# RZN2H register map
Vendor: Renesas Electronics Corporation; Series: RZN; File version: 1.00.00
CPU: other r0p0, little endian, MPU, no FPU, VTOR, 4 interrupt priority bits, 624 interrupts
Registers are 32-bit, read-write, reset 0x0 unless marked. A register's access mark holds for its fields unless they carry their own. Offsets are from the block's base; [hi:lo] are bit positions; {n}, {i} and the like mark numbered series; 'fields as' and 'values as' point back to an identical list; <NAME> marks a mode.

## DSMIF0 — Delta-sigma Interface 0
Base 0x90020000
Same registers: DSMIF1 0x90021000, DSMIF2 0x90022000, DSMIF3 0x90023000, DSMIF4 0x90024000, DSMIF5 0x90025000, DSMIF6 0x90120000, DSMIF7 0x90121000, DSMIF8 0x90122000, DSMIF9 0x90123000
0x00 DSCCSCR — Core Clock Selection Control Register
  [0] CLKSEL
    0=250 MHz; 1=400 MHz
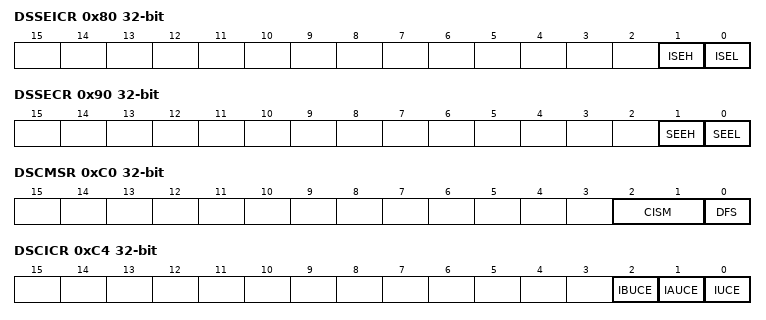
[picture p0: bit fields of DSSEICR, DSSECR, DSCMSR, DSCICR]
0x80 DSSEICR — Overcurrent Sum Error Detect Interrupt Control Register
  [1] ISEH — Overcurrent sum error upper limit detection interrupt enable bit
    0=Do not output overcurrent sum error upper limit detection interrupt; 1=Overcurrent sum error lower upper detection interrupt can be output
  [0] ISEL — Overcurrent sum error lower limit detection interrupt enable bit
    0=Do not output overcurrent sum error lower limit detection interrupt; 1=Overcurrent sum error lower limit detection interrupt can be output
0x84 DSSECSR — Overcurrent Sum Error Detect Channel Setting Register
  [2:0] SEDM — Overcurrent sum error detect mode setting bit
    0=Detects error of sum value of overcurrent data of CH0, CH1, CH2; 1=Detects error of sum value of overcurrent data of CH0, CH1; 2=Detects error of overcurrent data of CH0; 3=Detects error of overcurrent data of CH1; 4=Detects error of overcurrent data of CH2; other=Others (Setting prohibited (detects error of sum value of overcurrent data of CH0, CH1, CH2))
0x88 DSSELTR — Overcurrent Sum Error Detect Low Threshold Register
  [17:0] SCMPTBL — Overcurrent sum error detect lower limit
0x8C DSSEHTR — Overcurrent Sum Error Detect High Threshold Register
  [17:0] SCMPTBH — Overcurrent sum error detect upper limit
0x90 DSSECR — Overcurrent Sum Error Detect Control Register
  [1] SEEH — Overcurrent sum error upper limit detection enable bit
    0=The upper limit exceeded detection function of overcurrent sum error detection is invalid; 1=The upper limit exceeded detection function of overcurrent sum error detection is valid
  [0] SEEL — Overcurrent sum error lower limit detection enable bit
    0=The lower limit exceeded detection function of overcurrent sum error detection is invalid; 1=The lower limit exceeded detection function of overcurrent sum error detection is valid
{0xA0+4i} DSSECDR{i} (i=0..2) — Overcurrent Sum Error Detect Capture Data Register {i}
  [15:0] SECDR — Overcurrent sum error detect capture data n
0xC0 DSCMSR — Common Mode Setting Register
  [2:1] CISM — Common Interrupt Synchronous channel Mode
    0=Common interrupts are not used; 1=Common interrupts for ch0, ch1, and ch2 can be used; 2=Common interrupts for ch0 and ch1 can be used; 3=Setting prohibited
  [0] DFS — Data Format Select
    0=Left justified; 1=Right justified
0xC4 DSCICR — Common Interrupt Control Register
  [2] IBUCE — Capture current data register B update channel common interrupt enable
    0=Do not output capture current data register B update channel common interrupt; 1=Capture current data register B update channel common interrupt can be output
  [1] IAUCE — Capture current data register A update channel common interrupt enable
    0=Do not output capture current data register A update channel common interrupt; 1=Capture current data register A update channel common interrupt can be output
  [0] IUCE — Current data register update channel common interrupt enable
    0=Do not output capture current data register update channel common interrupt; 1=Capture current data register update channel common interrupt can be output
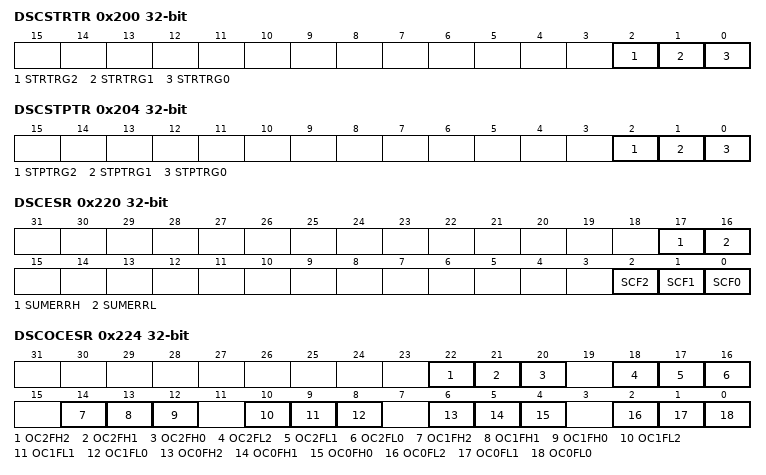
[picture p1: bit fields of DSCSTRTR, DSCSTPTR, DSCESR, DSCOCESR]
0x200 DSCSTRTR — Channel Software Start Trigger Register
  [all] fields
    0=Do nothing; 1=Start channel
  [2] STRTRG2 — Channel 2 start trigger
  [1] STRTRG1 — Channel 1 start trigger
  [0] STRTRG0 — Channel 0 start trigger
0x204 DSCSTPTR — Channel Software Stop Trigger Register
  [all] fields
    0=Do nothing; 1=Stop channel
  [2] STPTRG2 — Channel 2 stop trigger
  [1] STPTRG1 — Channel 1 stop trigger
  [0] STPTRG0 — Channel 0 stop trigger
0x220 DSCESR ro — Channel Error Status Register
  [17] SUMERRH — Overcurrent sum error upper limit detection flag
    0=Indicates that the sum value of overcurrent data is not more than the upper limit; 1=Indicates that the sum value of overcurrent data is more than the upper limit
  [16] SUMERRL — Overcurrent sum error lower limit detection flag
    0=Indicates that the sum value of overcurrent data is not less than the lower limit; 1=Indicates that the sum value of overcurrent data is less than the lower limit
  [2] SCF2 — Channel 2 short circuit detection flag
    0=Indicates that the MDATm2 pin short circuit is not detected; 1=Indicates that a short circuit on the MDATm2 pin has been detected
  [1] SCF1 — Channel 1 short circuit detection flag
    0=Indicates that the MDATm1 pin short circuit is not detected; 1=Indicates that a short circuit on the MDATm1 pin has been detected
  [0] SCF0 — Channel 0 short circuit detection flag
    0=Indicates that the MDATm0 pin short circuit is not detected; 1=Indicates that a short circuit on the MDATm0 pin has been detected
0x224 DSCOCESR ro — Channel Overcurrent Error Status Register
  [22] OC2FH2 — Channel 2 overcurrent upper limit exceeded 2 flag
    0=Indicates that the overcurrent data doesn't exceed the upper limit 2; 1=Indicates that the overcurrent data has exceeded the upper limit 2
  [21] OC2FH1 — Channel 1 overcurrent upper limit exceeded 2 flag
    values as OC2FH2
  [20] OC2FH0 — Channel 0 overcurrent upper limit exceeded 2 flag
    values as OC2FH2
  [18] OC2FL2 — Channel 2 overcurrent lower limit detection 2 flag
    0=Indicates that the overcurrent data is not less than the lower limit 2; 1=Indicates that the overcurrent data has been less than the lower limit 2
  [17] OC2FL1 — Channel 1 overcurrent lower limit detection 2 flag
    values as OC2FL2
  [16] OC2FL0 — Channel 0 overcurrent lower limit detection 2 flag
    values as OC2FL2
  [14] OC1FH2 — Channel 2 overcurrent upper limit exceeded 1 flag
    0=Indicates that the overcurrent data doesn't exceed the upper limit 1; 1=Indicates that the overcurrent data has exceeded the upper limit 1
  [13] OC1FH1 — Channel 1 overcurrent upper limit exceeded 1 flag
    values as OC1FH2
  [12] OC1FH0 — Channel 0 overcurrent upper limit exceeded 1 flag
    values as OC1FH2
  [10] OC1FL2 — Channel 2 overcurrent lower limit detection 1 flag
    0=Indicates that the overcurrent data is not less than the lower limit 1; 1=Indicates that the overcurrent data has been less than the lower limit 1
  [9] OC1FL1 — Channel 1 overcurrent lower limit detection 1 flag
    values as OC1FL2
  [8] OC1FL0 — Channel 0 overcurrent lower limit detection 1 flag
    values as OC1FL2
  [6] OC0FH2 — Channel 2 overcurrent upper limit exceeded 0 flag
    0=Indicates that the overcurrent data doesn't exceed the upper limit 0; 1=Indicates that the overcurrent data has exceeded the upper limit 0
  [5] OC0FH1 — Channel 1 overcurrent upper limit exceeded 0 flag
    values as OC0FH2
  [4] OC0FH0 — Channel 0 overcurrent upper limit exceeded 0 flag
    values as OC0FH2
  [2] OC0FL2 — Channel 2 overcurrent lower limit detection 0 flag
    0=Indicates that the overcurrent data is not less than the lower limit 0; 1=Indicates that the overcurrent data has been less than the lower limit 0
  [1] OC0FL1 — Channel 1 overcurrent lower limit detection 0 flag
    values as OC0FL2
  [0] OC0FL0 — Channel 0 overcurrent lower limit detection 0 flag
    values as OC0FL2
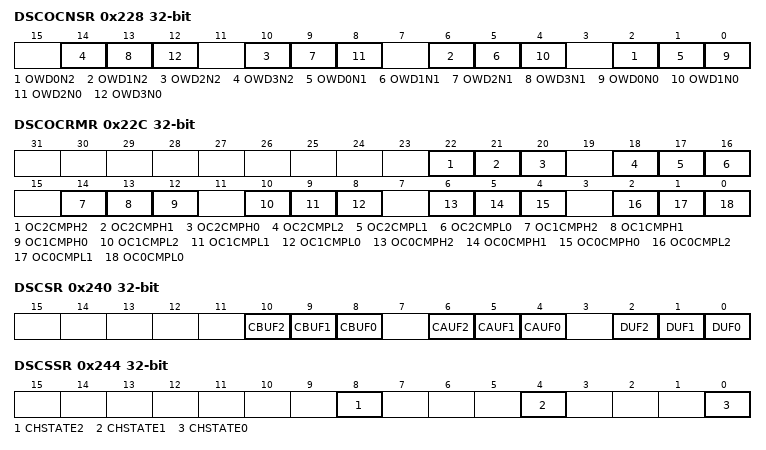
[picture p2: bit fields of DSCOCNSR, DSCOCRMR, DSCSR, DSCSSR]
0x228 DSCOCNSR ro — Channel Overcurrent Notification Status Register
  [4n+2] OWD{n}N2 (n=0..3) — Channel 2 overcurrent detection window notification {n} flag
    0=Indicates that the condition of overcurrent detection window notification {n} is not satisfied; 1=Indicates that the condition of overcurrent detection window notification {n} was satisfied
  [4n+1] OWD{n}N1 (n=0..3) — Channel 1 overcurrent detection window notification {n} flag
    values as OWD0N2
  [4n] OWD{n}N0 (n=0..3) — Channel 0 overcurrent detection window notification {n} flag
    values as OWD0N2
0x22C DSCOCRMR ro — Channel Overcurrent Comparator Result Monitor Register
  [22] OC2CMPH2 — Channel 2 overcurrent detect 2 upper limit compare result
    0=Indicates that the overcurrent data does not exceed the upper limit 2; 1=Indicates that the overcurrent data has exceeded the upper limit 2
  [21] OC2CMPH1 — Channel 1 overcurrent detect 2 upper limit compare result
    values as OC2CMPH2
  [20] OC2CMPH0 — Channel 0 overcurrent detect 2 upper limit compare result
    values as OC2CMPH2
  [18] OC2CMPL2 — Channel 2 overcurrent detect 2 lower limit compare result
    values as DSCOCESR.OC2FL2
  [17] OC2CMPL1 — Channel 1 overcurrent detect 2 lower limit compare result
    values as DSCOCESR.OC2FL2
  [16] OC2CMPL0 — Channel 0 overcurrent detect 2 lower limit compare result
    values as DSCOCESR.OC2FL2
  [14] OC1CMPH2 — Channel 2 overcurrent detect 1 upper limit compare result
    0=Indicates that the overcurrent data does not exceed the upper limit 1; 1=Indicates that the overcurrent data has exceeded the upper limit 1
  [13] OC1CMPH1 — Channel 1 overcurrent detect 1 upper limit compare result
    values as OC1CMPH2
  [12] OC1CMPH0 — Channel 0 overcurrent detect 1 upper limit compare result
    values as OC1CMPH2
  [10] OC1CMPL2 — Channel 2 overcurrent detect 1 lower limit compare result
    values as DSCOCESR.OC1FL2
  [9] OC1CMPL1 — Channel 1 overcurrent detect 1 lower limit compare result
    values as DSCOCESR.OC1FL2
  [8] OC1CMPL0 — Channel 0 overcurrent detect 1 lower limit compare result
    values as DSCOCESR.OC1FL2
  [6] OC0CMPH2 — Channel 2 overcurrent detect 0 upper limit compare result
    0=Indicates that the overcurrent data does not exceed the upper limit 0; 1=Indicates that the overcurrent data has exceeded the upper limit 0
  [5] OC0CMPH1 — Channel 1 overcurrent detect 0 upper limit compare result
    values as OC0CMPH2
  [4] OC0CMPH0 — Channel 0 overcurrent detect 0 upper limit compare result
    values as OC0CMPH2
  [2] OC0CMPL2 — Channel 2 overcurrent detect 0 lower limit compare result
    values as DSCOCESR.OC0FL2
  [1] OC0CMPL1 — Channel 1 overcurrent detect 0 lower limit compare result
    values as DSCOCESR.OC0FL2
  [0] OC0CMPL0 — Channel 0 overcurrent detect 0 lower limit compare result
    values as DSCOCESR.OC0FL2
0x240 DSCSR ro — Channel Status Register
  [10] CBUF2 — Channel 2 capture data B update flag
    0=Indicates that the capture register B has not been updated; 1=Indicates that the capture register B has been updated
  [9] CBUF1 — Channel 1 capture data B update flag
    values as CBUF2
  [8] CBUF0 — Channel 0 capture data B update flag
    values as CBUF2
  [6] CAUF2 — Channel 2 capture data A update flag
    0=Indicates that the capture register A has not been updated; 1=Indicates that the capture register A has been updated
  [5] CAUF1 — Channel 1 capture data A update flag
    values as CAUF2
  [4] CAUF0 — Channel 0 capture data A update flag
    values as CAUF2
  [2] DUF2 — Channel 2 Data Update flag
    0=Indicates that the Current Data register has not been updated; 1=Indicates that the Current Data register has been updated
  [1] DUF1 — Channel 1 Data Update flag
    values as DUF2
  [0] DUF0 — Channel 0 Data Update flag
    values as DUF2
0x244 DSCSSR ro — Channel State Status Register
  [all] fields
    0=Channel stop; 1=Channel in operation
  [8] CHSTATE2 — Channel 2 state
  [4] CHSTATE1 — Channel 1 state
  [0] CHSTATE0 — Channel 0 state
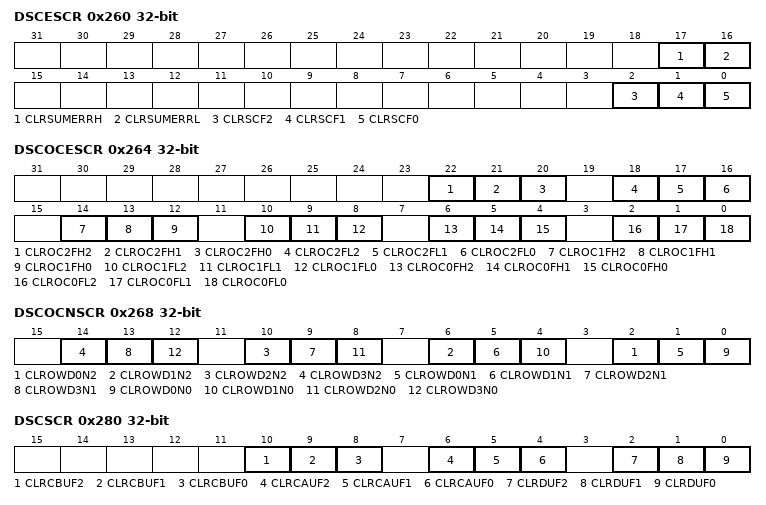
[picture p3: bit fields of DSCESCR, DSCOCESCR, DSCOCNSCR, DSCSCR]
0x260 DSCESCR wo — Channel Error Status Clear Register
  [17] CLRSUMERRH — Overcurrent Sum Error Upper Limit Detection Flag Clear
    0=No effect; 1=Clear DSCESR.SUMERRH
  [16] CLRSUMERRL — Overcurrent Sum Error Lower Limit Detection Flag Clear
    0=No effect; 1=Clear DSCESR.SUMERRL
  [2] CLRSCF2 — Channel 2 Overcurrent Lower Limit Detection Flag Clear
    0=No effect; 1=Clear DSCESR.OCFL2 / DSCSRCH2.OCFL
  [1] CLRSCF1 — Channel 1 Overcurrent Lower Limit Detection Flag Clear
    0=No effect; 1=Clear DSCESR.OCFL1 / DSCSRCH1.OCFL
  [0] CLRSCF0 — Channel 0 Overcurrent Lower Limit Detection Flag Clear
    0=No effect; 1=Clear DSCESR.OCFL0 / DSCSRCH0.OCFL
0x264 DSCOCESCR wo — Channel Overcurrent Error Status Clear Register
  [22] CLROC2FH2 — Channel 2 overcurrent upper limit exceeded 2 flag clear
    0=No effect; 1=Clear DSCOCESR.OC2FH2 / DSCSRCH2.OC2FH
  [21] CLROC2FH1 — Channel 1 overcurrent upper limit exceeded 2 flag
    0=No effect; 1=Clear DSCOCESR.OC2FH1 / DSCSRCH1.OC2FH
  [20] CLROC2FH0 — Channel 0 overcurrent upper limit exceeded 2 flag clear
    0=No effect; 1=Clear DSCOCESR.OC2FH0 / DSCSRCH0.OC2FH
  [18] CLROC2FL2 — Channel 2 overcurrent lower limit detection 2 flag clear
    0=No effect; 1=Clear DSCOCESR.OC2FL2 / DSCSRCH2.OC2FL
  [17] CLROC2FL1 — Channel 1 overcurrent lower limit detection 2 flag clear
    0=No effect; 1=Clear DSCOCESR.OC2FL1 / DSCSRCH1.OC2FL
  [16] CLROC2FL0 — Channel 0 overcurrent lower limit detection 2 flag clear
    0=No effect; 1=Clear DSCOCESR.OC2FL0 / DSCSRCH0.OC2FL
  [14] CLROC1FH2 — Channel 2 overcurrent upper limit exceeded 1 flag clear
    0=No effect; 1=Clear DSCOCESR.OC1FH2 / DSCSRCH2.OC1FH
  [13] CLROC1FH1 — Channel 1 overcurrent upper limit exceeded 1 flag clear
    0=No effect; 1=Clear DSCOCESR.OC1FH1 / DSCSRCH1.OC1FH
  [12] CLROC1FH0 — Channel 0 overcurrent upper limit exceeded 1 flag clear
    0=No effect; 1=Clear DSCOCESR.OC1FH0 / DSCSRCH0.OC1FH
  [10] CLROC1FL2 — Channel 2 overcurrent lower limit detection 1 flag clear
    0=No effect; 1=Clear DSCOCESR.OC1FL2 / DSCSRCH2.OC1FL
  [9] CLROC1FL1 — Channel 1 overcurrent lower limit detection 1 flag clear
    0=No effect; 1=Clear DSCOCESR.OC1FL1 / DSCSRCH1.OC1FL
  [8] CLROC1FL0 — Channel 0 overcurrent lower limit detection 1 flag clear
    0=No effect; 1=Clear DSCOCESR.OC1FL0 / DSCSRCH0.OC1FL
  [6] CLROC0FH2 — Channel 2 overcurrent upper limit exceeded 0 flag clear
    0=No effect; 1=Clear DSCOCESR.OC0FH2 / DSCSRCH2.OC0FH
  [5] CLROC0FH1 — Channel 1 overcurrent upper limit exceeded 0 flag clear
    0=No effect; 1=Clear DSCOCESR.OC0FH1 / DSCSRCH1.OC0FH
  [4] CLROC0FH0 — Channel 0 overcurrent upper limit exceeded 0 flag clear
    0=No effect; 1=Clear DSCOCESR.OC0FH0 / DSCSRCH0.OC0FH
  [2] CLROC0FL2 — Channel 2 overcurrent lower limit detection 0 flag clear
    0=No effect; 1=Clear DSCOCESR.OC0FL2 / DSCSRCH2.OC0FL
  [1] CLROC0FL1 — Channel 1 overcurrent lower limit detection 0 flag clear
    0=No effect; 1=Clear DSCOCESR.OC0FL1 / DSCSRCH1.OC0FL
  [0] CLROC0FL0 — Channel 0 overcurrent lower limit detection 0 flag clear
    0=No effect; 1=Clear DSCOCESR.OC0FL0 / DSCSRCH0.OC0FL
0x268 DSCOCNSCR wo — Channel Overcurrent Notification Status Clear Register
  [4n+2] CLROWD{n}N2 (n=0..3) — Channel 2 overcurrent detection window notification {n} flag clear
    0=No effect; 1=Clear DSCOCNSR.OWD{n}N2 / DSCSRCH2.OWD{n}N
  [4n+1] CLROWD{n}N1 (n=0..3) — Channel 1 overcurrent detection window notification {n} flag clear
    0=No effect; 1=Clear DSCOCNSR.OWD{n}N1 / DSCSRCH1.OWD{n}N
  [4n] CLROWD{n}N0 (n=0..3) — Channel 0 overcurrent detection window notification {n} flag clear
    0=No effect; 1=Clear DSCOCNSR.OWD{n}N0 / DSCSRCH0.OWD{n}N
0x280 DSCSCR wo — Channel Status Clear Register
  [10] CLRCBUF2 — Channel 2 Capture Data B Update Flag Clear
    0=No effect; 1=Clear DSCSR.CBUF2 / DSCSRCH2.CBUF
  [9] CLRCBUF1 — Channel 1 Capture Data B Update Flag Clear
    0=No effect; 1=Clear DSCSR.CBUF1 / DSCSRCH1.CBUF
  [8] CLRCBUF0 — Channel 0 Capture Data B Update Flag Clear
    0=No effect; 1=Clear DSCSR.CBUF0 / DSCSRCH0.CBUF
  [6] CLRCAUF2 — Channel 2 Capture Data A Update Flag Clear
    0=No effect; 1=Clear DSCSR.CAUF2 / DSCSRCH2.CAUF
  [5] CLRCAUF1 — Channel 1 Capture Data A Update Flag Clear
    0=No effect; 1=Clear DSCSR.CAUF1 / DSCSRCH1.CAUF
  [4] CLRCAUF0 — Channel 0 Capture Data A Update Flag Clear
    0=No effect; 1=Clear DSCSR.CAUF0 / DSCSRCH0.CAUF
  [2] CLRDUF2 — Channel 2 Data Update Flag Clear
    0=No effect; 1=Clear DSCSR.DUF2 / DSCSRCH2.DUF
  [1] CLRDUF1 — Channel 1 Data Update Flag Clear
    0=No effect; 1=Clear DSCSR.DUF1 / DSCSRCH1.DUF
  [0] CLRDUF0 — Channel 0 Data Update Flag Clear
    0=No effect; 1=Clear DSCSR.DUF0 / DSCSRCH0.DUF
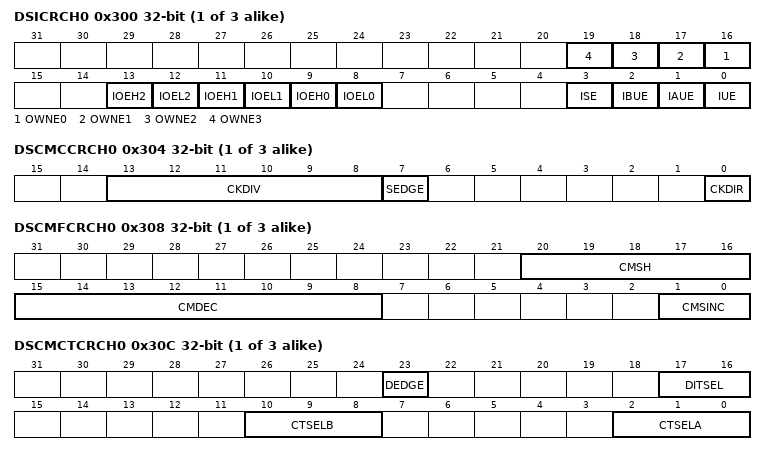
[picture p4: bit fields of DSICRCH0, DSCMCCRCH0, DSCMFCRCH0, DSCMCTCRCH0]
{0x300+0x140*i} DSICRCH{i} (i=0..2) — Interrupt Control Register Channel {i}
  [n+16] OWNE{n} (n=0..3) — Overcurrent detection window notification {n} output enable
    0=Do not output overcurrent detection window notification {n}; 1=Overcurrent detection window notification {n} can be output
  [13] IOEH2 — Overcurrent upper limit exceeded detection interrupt 2
    0=Do not output the overcurrent upper limit detection interrupt 2; 1=Overcurrent upper limit exceeded detection interrupt 2 can be output
  [12] IOEL2 — Overcurrent lower limit detection interrupt 2
    0=Do not output the overcurrent lower limit detection interrupt 2; 1=Overcurrent lower limit detection interrupt 2 can be output
  [11] IOEH1 — Overcurrent upper limit exceeded detection interrupt 1
    0=Do not output the overcurrent upper limit detection interrupt 1; 1=Overcurrent upper limit exceeded detection interrupt 1 can be output
  [10] IOEL1 — Overcurrent lower limit detection interrupt 1
    0=Do not output the overcurrent lower limit detection interrupt 1; 1=Overcurrent lower limit detection interrupt 1 can be output
  [9] IOEH0 — Overcurrent upper limit exceeded detection interrupt 0
    0=Do not output the overcurrent upper limit detection interrupt 0; 1=Overcurrent upper limit exceeded detection interrupt 0 can be output
  [8] IOEL0 — Overcurrent lower limit detection interrupt 0
    0=Do not output the overcurrent lower limit detection interrupt 0; 1=Overcurrent lower limit detection interrupt 0 can be output
  [3] ISE — Short circuit detection error interrupt enable bit
    0=Do not output short circuit detection interrupt; 1=Short circuit detection interrupt can be output
  [2] IBUE — Capture current data register B update interrupt enable
    0=Do not output capture current data register B update interrupt; 1=Capture current data register B update interrupt can be output
  [1] IAUE — Capture current data register A update interrupt enable
    0=Do not output capture current data register A update interrupt; 1=Capture current data register A update interrupt can be output
  [0] IUE — Current data register update interrupt enable
    0=Do not output current data register update interrupt; 1=Current data register update interrupt can be output
{0x304+0x140*i} DSCMCCRCH{i} (i=0..2) — Current Measurement Clock Control Register Channel {i}
  [13:8] CKDIV — A/D conversion clock division ratio
  [7] SEDGE — Sampling edge selection
    0=Capture MDATmn at the negative edge of MCLKmn; 1=Capture MDATmn at the positive edge of MCLKmn
  [0] CKDIR — A/D conversion clock master/slave switching
    0=MCLKmn pin is input (slave operation); 1=MCLKmn pin is output (master operation)
{0x308+0x140*i} DSCMFCRCH{i} (i=0..2) — Current Measurement Filter Control Register Channel {i}
  [20:16] CMSH — Data shift setting for current measurement
    0=[23:8]; 1=[22:7]; 2=[21:6]; 3=[20:5]; 4=[19:4]; 5=[18:3]; 6=[17:2]; 7=[16:1]; 8=[15:0]; 9=[14:0]<<1; 10=[13:0]<<2; 11=[12:0]<<3; 12=[11:0]<<4; 13=[10:0]<<5; 14=[9:0]<<6; 15=[8:0]<<7; 16=[7:0]<<8; 17=[6:0]<<9; 18=[5:0]<<10; 19=[4:0]<<11; other=Others (Setting prohibited)
  [15:8] CMDEC — Decimation ratio selection for current measurement
  [1:0] CMSINC — Current measurement filter order setting
    0=Sinc3 (3rd order); 1=Sinc1 (1st order); 2=Sinc2 (2nd order); 3=Setting prohibited
{0x30C+0x140*i} DSCMCTCRCH{i} (i=0..2) — Current Measurement Capture Trigger Control Register Channel {i}
  [23] DEDGE — Current measurement filter initialization trigger for division counter for decimation edge selection bit. The trigger from ELC is usually used positive edge. Change from the initial value if necessary.
    0=The frequency division counter for decimation is initialized at the negative edge of initialization trigger; 1=The frequency division counter for decimation is initialized at the positive edge of initialization trigger
  [17:16] DITSEL — Current measurement filter initialization trigger selection bit for frequency division counter for decimation.
    0=Do not initialize; 1=Select decimation dividing counter initialization trigger 0; 2=Select decimation dividing counter initialization trigger 1; 3=Select decimation dividing counter initialization trigger 2
  [10:8] CTSELB — Current capture trigger B selection bit
    0=Do not capture; {v}=Select current data capture trigger {v-1} (v=1..6); 7=Setting prohibited (do not capture)
  [2:0] CTSELA — Current capture trigger A selection bit
    values as CTSELB
{0x320+0x140*i} DSEDCRCH{i} (i=0..2) — Error Detect Control Register Channel {i}
  [0] SDE — Short circuit detection enable bit
    0=Short circuit detection is invalid; 1=Short circuit detection is valid
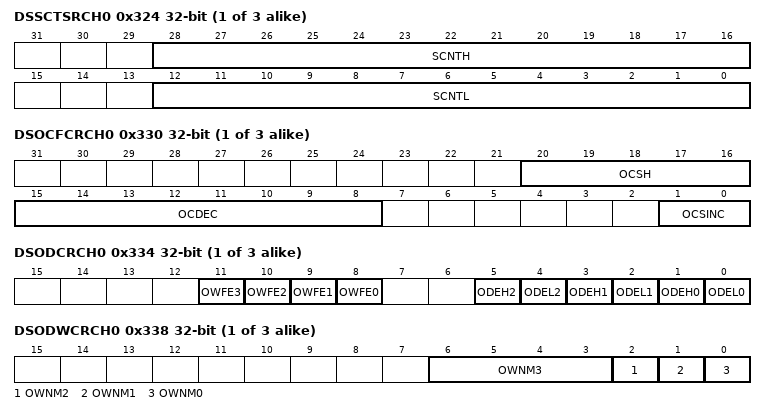
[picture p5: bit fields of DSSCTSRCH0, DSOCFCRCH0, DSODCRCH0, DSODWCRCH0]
{0x324+0x140*i} DSSCTSRCH{i} (i=0..2) — Short Circuit Threshold Setting Register Channel {i}
  [28:16] SCNTH — Short circuit detection high continuous detection count
  [12:0] SCNTL — Short circuit detection low continuous detection count
{0x330+0x140*i} DSOCFCRCH{i} (i=0..2) — Overcurrent Detect Filter Control Register Channel {i}
  [20:16] OCSH — Data shift setting for overcurrent detection
    values as DSCMFCRCH0.CMSH
  [15:8] OCDEC — Decimation ratio selection for overcurrent detection
  [1:0] OCSINC — Overcurrent detection filter order setting
    values as DSCMFCRCH0.CMSINC
{0x334+0x140*i} DSODCRCH{i} (i=0..2) — Overcurrent Detect Control Register Channel {i}
  [11] OWFE3 — Overcurrent detection window function 2 enable
    0=Overcurrent detection window function 2 is invalid; 1=Overcurrent detection window function 2 is valid
  [10] OWFE2 — Overcurrent detection window function 1 enable
    0=Overcurrent detection window function 1 is invalid; 1=Overcurrent detection window function 1 is valid
  [9] OWFE1 — Overcurrent detection window function 0 enable
    0=Overcurrent detection window function 0 is invalid; 1=Overcurrent detection window function 0 is valid
  [8] OWFE0 — Overcurrent lower limit detection interrupt 0
    values as DSICRCH0.IOEL0
  [5] ODEH2 — Overcurrent upper limit exceeded detection 2 enable
    0=Overcurrent upper limit exceeded detection 2 is invalid; 1=Overcurrent upper limit exceeded detection 2 is valid
  [4] ODEL2 — Overcurrent lower limit detection 2 enable
    0=Overcurrent lower limit detection 2 is invalid; 1=Overcurrent lower limit detection 2 is valid
  [3] ODEH1 — Overcurrent upper limit exceeded detection 1 enable
    0=Overcurrent upper limit exceeded detection 1 is invalid; 1=Overcurrent upper limit exceeded detection 1 is valid
  [2] ODEL1 — Overcurrent lower limit detection 1 enable
    0=Overcurrent lower limit detection 1 is invalid; 1=Overcurrent lower limit detection 1 is valid
  [1] ODEH0 — Overcurrent upper limit exceeded detection 0 enable
    0=Overcurrent upper limit exceeded detection 0 is invalid; 1=Overcurrent upper limit exceeded detection 0 is valid
  [0] ODEL0 — Overcurrent lower limit detection 0 enable
    0=Overcurrent lower limit detection 0 is invalid; 1=Overcurrent lower limit detection 0 is valid
{0x338+0x140*i} DSODWCRCH{i} (i=0..2) — Overcurrent Detect Window Control Register Channel {i}
  [6:3] OWNM3 — Channel n overcurrent detection window notification 3 mode select
    0=Overcurrent detection window notification 0; 1=Overcurrent detection window notification 1; 2=Overcurrent detection window notification 2; 3=Overcurrent detection window notification 0 OR overcurrent detection window notification 1; 4=Overcurrent detection window notification 0 AND overcurrent detection window notification 1; 5=Overcurrent detection window notification 0 OR overcurrent detection window notification 2; 6=Overcurrent detection window notification 0 AND overcurrent detection window notification 1; 7=Overcurrent detection window notification 1 OR overcurrent detection window notification 2; 8=Overcurrent detection window notification 1 AND overcurrent detection window notification 2; 9=Overcurrent detection window notification 0 OR overcurrent detection window notification 1 OR overcurrent detection window notification 2; 10=Overcurrent detection window notification 0 AND overcurrent detection window notification 1 AND overcurrent detection window notification 2; other=Others (Setting prohibited)
  [2] OWNM2 — Channel n overcurrent detection window notification 2 mode select
    0=(overcurrent data channel n < lower limit 2) or (overcurrent data channel n > upper limit 2); 1=lower limit 2 channel n <= overcurrent data channel n <= upper limit 2 channel n
  [1] OWNM1 — Channel n overcurrent detection window notification 1 mode select
    0=(overcurrent data channel n < lower limit 1) or (overcurrent data channel n > upper limit 1); 1=lower limit 1 channel n <= overcurrent data channel n <= upper limit 1 channel n
  [0] OWNM0 — Channel n overcurrent detection window notification 0 mode select
    0=(overcurrent data channel n < lower limit 0) or (overcurrent data channel n > upper limit 0); 1=lower limit 0 channel n <= overcurrent data channel n <= upper limit 0 channel n
{0x3A0+0x140*i} DSOCLTR0CH{i} (i=0..2) — Overcurrent Low Threshold Register 0 Channel {i}
  [15:0] OCMPTBL0 — Overcurrent detection lower limit 0
{0x3A4+0x140*i} DSOCHTR0CH{i} (i=0..2) — Overcurrent High Threshold Register 0 Channel {i}
  [15:0] OCMPTBH0 — Overcurrent detection upper limit 0
{0x3A8+0x140*i} DSOCLTR1CH{i} (i=0..2) — Overcurrent Low Threshold Register 1 Channel {i}
  [15:0] OCMPTBL1 — Overcurrent detection lower limit 1
{0x3AC+0x140*i} DSOCHTR1CH{i} (i=0..2) — Overcurrent High Threshold Register 1 Channel {i}
  [15:0] OCMPTBH1 — Overcurrent detection upper limit 1
{0x3B0+0x140*i} DSOCLTR2CH{i} (i=0..2) — Overcurrent Low Threshold Register 2 Channel {i}
  [15:0] OCMPTBL2 — Overcurrent detection lower limit 2
{0x3B4+0x140*i} DSOCHTR2CH{i} (i=0..2) — Overcurrent High Threshold Register 2 Channel {i}
  [15:0] OCMPTBH2 — Overcurrent detection upper limit 2
{0x3E0+0x140*i} DSCSTRTRCH{i} (i=0..2) — Software Start Trigger Register Channel {i}
  [0] STRTRG — Channel start trigger
    0=Do nothing; 1=Start channel n
{0x3E4+0x140*i} DSCSTPTRCH{i} (i=0..2) — Software Stop Trigger Register Channel {i}
  [0] STPTRG — Channel stop trigger
    0=Do nothing; 1=Stop channel n
{0x3F0+0x140*i} DSCDRCH{i} (i=0..2) ro — Current Data Register Channel {i}
  [15:0] ADDR — Current data
{0x3F4+0x140*i} DSCCDRACH{i} (i=0..2) ro — Capture Current Data Register A Channel {i}
  [15:0] CDRA — Capture current data A
{0x3F8+0x140*i} DSCCDRBCH{i} (i=0..2) ro — Capture Current Data Register B Channel {i}
  [15:0] CDRB — Capture current data B
{0x3FC+0x140*i} DSOCDRCH{i} (i=0..2) ro — Overcurrent Data Register Channel {i}
  [15:0] ODR — Overcurrent data
{0x400+0x140*i} DSCOCDR0CH{i} (i=0..2) ro — Capture Overcurrent Data Register 0 Channel {i}
  [15:0] CODR0 — Capture overcurrent data 0
{0x404+0x140*i} DSCOCDR1CH{i} (i=0..2) ro — Capture Overcurrent Data Register 1 Channel {i}
  [15:0] CODR1 — Capture overcurrent data 1
{0x408+0x140*i} DSCOCDR2CH{i} (i=0..2) ro — Capture Overcurrent Data Register 2 Channel {i}
  [15:0] CODR2 — Capture overcurrent data 2
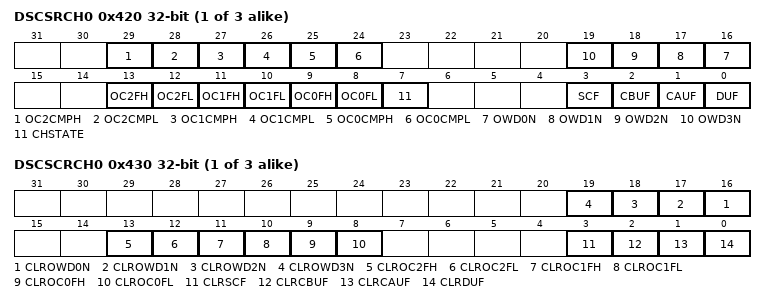
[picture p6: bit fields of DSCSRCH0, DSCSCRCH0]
{0x420+0x140*i} DSCSRCH{i} (i=0..2) ro — Status Register Channel {i}
  [29] OC2CMPH — Channel n overcurrent detect 2 upper limit compare result
    values as DSCOCESR.OC2FH2
  [28] OC2CMPL — Channel n overcurrent detect 2 lower limit compare result
    0=Indicates that the overcurrent data is not less than the lower limit 2; 1=Indicates that the overcurrent data has fallen the lower limit 2
  [27] OC1CMPH — Channel n overcurrent detect 1 upper limit compare result
    values as DSCOCESR.OC1FH2
  [26] OC1CMPL — Channel n overcurrent detect 1 lower limit compare result
    0=Indicates that the overcurrent data is not less than the lower limit 1; 1=Indicates that the overcurrent data has fallen the lower limit 1
  [25] OC0CMPH — Channel n overcurrent detect 0 upper limit compare result
    values as DSCOCESR.OC0FH2
  [24] OC0CMPL — Channel n overcurrent detect 0 lower limit compare result
    0=Indicates that the overcurrent data is not less than the lower limit 0; 1=Indicates that the overcurrent data has fallen the lower limit 0
  [n+16] OWD{n}N (n=0..3) — Channel n overcurrent detection window notification {n}
    values as DSCOCNSR.OWD0N2
  [13] OC2FH — Channel n overcurrent upper limit exceeded 2 flag
    values as DSCOCESR.OC2FH2
  [12] OC2FL — Channel n overcurrent lower limit detection 2 flag
    values as DSCOCESR.OC2FL2
  [11] OC1FH — Channel n overcurrent upper limit exceeded 1 flag
    values as DSCOCESR.OC1FH2
  [10] OC1FL — Channel n overcurrent lower limit detection 1 flag
    values as DSCOCESR.OC1FL2
  [9] OC0FH — Channel n overcurrent upper limit exceeded 0 flag
    values as DSCOCESR.OC0FH2
  [8] OC0FL — Channel n overcurrent lower limit detection 0 flag
    values as DSCOCESR.OC0FL2
  [7] CHSTATE — Channel n state
    0=Channel stop; 1=Channel in operation
  [3] SCF — Channel n short circuit detection flag
    0=Indicates that the MDATmn pin short circuit is not detected; 1=Indicates that a short circuit on the MDATmn pin has been detected
  [2] CBUF — Channel n capture data B update flag
    0=Indicates that the capture data register B has not been updated; 1=Indicates that the capture data register B has been updated
  [1] CAUF — Channel n capture data A update flag
    0=Indicates that the capture data register A has not been updated; 1=Indicates that the capture data register A has been updated
  [0] DUF — Channel n data update flag
    0=Indicates that the current data register has not been updated; 1=Indicates that the current data register has been updated
{0x430+0x140*i} DSCSCRCH{i} (i=0..2) wo — Status Clear Register Channel {i}
  [n+16] CLROWD{n}N (n=0..3) — Channel n overcurrent detection window notification {n} flag clear
    0=Do nothing; 1=Clear DSCOCNSR.OWD{n}Nn / DSCSRCHn.OWD{n}N
  [13] CLROC2FH — Channel n overcurrent upper limit exceeded flag 2 clear
    0=Do nothing; 1=Clear DSCOCESR.OSC2FHn / DSCSRCHn.OC2FH
  [12] CLROC2FL — Channel n overcurrent lower limit detection flag 2 clear
    0=Do nothing; 1=Clear DSCOCESR.OSC2FLn / DSCSRCHn.OC2FL
  [11] CLROC1FH — Channel n overcurrent upper limit exceeded flag 1 clear
    0=Do nothing; 1=Clear DSCOCESR.OSC1FHn / DSCSRCHn.OC1FH
  [10] CLROC1FL — Channel n overcurrent lower limit detection flag 1 clear
    0=Do nothing; 1=Clear DSCOCESR.OSC1FLn / DSCSRCHn.OC1FL
  [9] CLROC0FH — Channel n overcurrent upper limit exceeded flag 0 clear
    0=Do nothing; 1=Clear DSCOCESR.OSC0FHn / DSCSRCHn.OC0FH
  [8] CLROC0FL — Channel n overcurrent lower limit detection flag 0 clear
    0=Do nothing; 1=Clear DSCOCESR.OSC0FLn / DSCSRCHn.OC0FL
  [3] CLRSCF — Channel n short circuit detection flag clear
    0=Do nothing; 1=Clear DSCESR.SCFn / DSCSRCHn.SCF
  [2] CLRCBUF — Channel n capture data B update flag clear
    0=Do nothing; 1=Clear DSCSR.CBUFn /DSCSRCHn.CBUF
  [1] CLRCAUF — Channel n capture data A update flag clear
    0=Do nothing; 1=Clear DSCSR.CAUFn /DSCSRCHn.CAUF
  [0] CLRDUF — Channel n data update flag clear
    0=Do nothing; 1=Clear DSCSR.DUFn /DSCSRCHn.DUF
